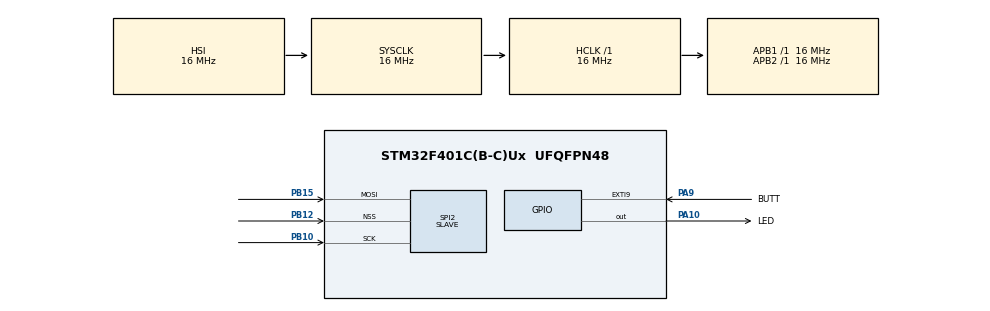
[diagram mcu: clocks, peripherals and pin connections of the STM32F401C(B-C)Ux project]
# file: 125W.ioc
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Mcu.Family=STM32F4
Mcu.Name=STM32F401C(B-C)Ux
Mcu.Package=UFQFPN48
NVIC.EXTI9_5_IRQn=true\:8\:0\:true\:false\:true\:true\:true\:true
NVIC.PriorityGroup=NVIC_PRIORITYGROUP_4
NVIC.SPI2_IRQn=true\:5\:0\:true\:false\:true\:true\:true\:true
PA10.GPIO_Label=LED
PA10.PinState=GPIO_PIN_SET
PA10.Signal=GPIO_Output
PA9.GPIO_Label=BUTT
PA9.GPIO_ModeDefaultEXTI=GPIO_MODE_IT_RISING
PA9.Signal=GPXTI9
PB10.Mode=RX_Only_Simplex_Unidirect_Slave
PB10.Signal=SPI2_SCK
PB12.Mode=NSS_Signal_Hard_Input
PB12.Signal=SPI2_NSS
PB15.Mode=RX_Only_Simplex_Unidirect_Slave
PB15.Signal=SPI2_MOSI
ProjectManager.HeapSize=0x200
ProjectManager.StackSize=0x400
ProjectManager.TargetToolchain=STM32CubeIDE
RCC.AHBFreq_Value=16000000
RCC.APB1Freq_Value=16000000
RCC.APB2Freq_Value=16000000
RCC.CortexFreq_Value=16000000
RCC.HSE_VALUE=25000000
RCC.HSI_VALUE=16000000
RCC.LSE_VALUE=32768
RCC.SYSCLKFreq_VALUE=16000000
RCC.VCOOutputFreq_Value=192000000
SPI2.Direction=SPI_DIRECTION_2LINES_RXONLY
SPI2.Mode=SPI_MODE_SLAVE
SPI2.VirtualNSS=VM_NSSHARD
SPI2.VirtualType=VM_SLAVE
board=custom

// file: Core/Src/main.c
/* USER CODE BEGIN Header */
/**
  ******************************************************************************
  * @file           : main.c
  * @brief          : Main program body
  ******************************************************************************
  * @attention
  *
  * Copyright (c) 2024 STMicroelectronics.
  * All rights reserved.
  *
  * This software is licensed under terms that can be found in the LICENSE file
  * in the root directory of this software component.
  * If no LICENSE file comes with this software, it is provided AS-IS.
  *
  ******************************************************************************
  */
/* USER CODE END Header */
#include "main.h"

SPI_HandleTypeDef hspi2;

/* USER CODE BEGIN PV */
uint8_t rx_buff = 0x00;
/* USER CODE END PV */

void SystemClock_Config(void);
static void MX_GPIO_Init(void);
static void MX_SPI2_Init(void);

int main(void)
{

  /* MCU Configuration--------------------------------------------------------*/

  /* Reset of all peripherals, Initializes the Flash interface and the Systick. */
  HAL_Init();

  /* Configure the system clock */
  SystemClock_Config();

  /* Initialize all configured peripherals */
  MX_GPIO_Init();
  MX_SPI2_Init();
  /* USER CODE BEGIN 2 */
  //uint8_t rx_buff = 0xff;

  HAL_SPI_Receive_IT (&hspi2, &rx_buff, sizeof(rx_buff));
  //HAL_SPI_Receive_IT (&hspi2, rx_buff, sizeof(rx_buff));
  //HAL_GPIO_ReadPin(BUTT_GPIOx_Port, BUTT_Pin);
  /* USER CODE END 2 */

  /* Infinite loop */
  /* USER CODE BEGIN WHILE */
  while (1)
  {
	  if (rx_buff) HAL_GPIO_WritePin(LED_GPIO_Port, LED_Pin, 0);
    /* USER CODE BEGIN 3 */
	 // if (rx_buff) HAL_GPIO_WritePin(LED_GPIO_Port, LED_Pin, 0);
  }
  /* USER CODE END 3 */
    /* USER CODE END WHILE */

  }

void SystemClock_Config(void)
{
  RCC_OscInitTypeDef RCC_OscInitStruct = {0};
  RCC_ClkInitTypeDef RCC_ClkInitStruct = {0};

  /** Configure the main internal regulator output voltage
  */
  __HAL_RCC_PWR_CLK_ENABLE();
  __HAL_PWR_VOLTAGESCALING_CONFIG(PWR_REGULATOR_VOLTAGE_SCALE2);

  /** Initializes the RCC Oscillators according to the specified parameters
  * in the RCC_OscInitTypeDef structure.
  */
  RCC_OscInitStruct.OscillatorType = RCC_OSCILLATORTYPE_HSI;
  RCC_OscInitStruct.HSIState = RCC_HSI_ON;
  RCC_OscInitStruct.HSICalibrationValue = RCC_HSICALIBRATION_DEFAULT;
  RCC_OscInitStruct.PLL.PLLState = RCC_PLL_NONE;
  if (HAL_RCC_OscConfig(&RCC_OscInitStruct) != HAL_OK)
  {
    Error_Handler();
  }

  /** Initializes the CPU, AHB and APB buses clocks
  */
  RCC_ClkInitStruct.ClockType = RCC_CLOCKTYPE_HCLK|RCC_CLOCKTYPE_SYSCLK
                              |RCC_CLOCKTYPE_PCLK1|RCC_CLOCKTYPE_PCLK2;
  RCC_ClkInitStruct.SYSCLKSource = RCC_SYSCLKSOURCE_HSI;
  RCC_ClkInitStruct.AHBCLKDivider = RCC_SYSCLK_DIV1;
  RCC_ClkInitStruct.APB1CLKDivider = RCC_HCLK_DIV1;
  RCC_ClkInitStruct.APB2CLKDivider = RCC_HCLK_DIV1;

  if (HAL_RCC_ClockConfig(&RCC_ClkInitStruct, FLASH_LATENCY_0) != HAL_OK)
  {
    Error_Handler();
  }
}

static void MX_SPI2_Init(void)
{

  /* SPI2 parameter configuration*/
  hspi2.Instance = SPI2;
  hspi2.Init.Mode = SPI_MODE_SLAVE;
  hspi2.Init.Direction = SPI_DIRECTION_2LINES_RXONLY;
  hspi2.Init.DataSize = SPI_DATASIZE_8BIT;
  hspi2.Init.CLKPolarity = SPI_POLARITY_LOW;
  hspi2.Init.CLKPhase = SPI_PHASE_1EDGE;
  hspi2.Init.NSS = SPI_NSS_HARD_INPUT;
  hspi2.Init.FirstBit = SPI_FIRSTBIT_MSB;
  hspi2.Init.TIMode = SPI_TIMODE_DISABLE;
  hspi2.Init.CRCCalculation = SPI_CRCCALCULATION_DISABLE;
  hspi2.Init.CRCPolynomial = 10;
  if (HAL_SPI_Init(&hspi2) != HAL_OK)
  {
    Error_Handler();
  }

}

static void MX_GPIO_Init(void)
{
  GPIO_InitTypeDef GPIO_InitStruct = {0};

  /* GPIO Ports Clock Enable */
  __HAL_RCC_GPIOB_CLK_ENABLE();
  __HAL_RCC_GPIOA_CLK_ENABLE();

  /*Configure GPIO pin Output Level */
  HAL_GPIO_WritePin(LED_GPIO_Port, LED_Pin, GPIO_PIN_SET);

  /*Configure GPIO pin : BUTT_Pin */
  GPIO_InitStruct.Pin = BUTT_Pin;
  GPIO_InitStruct.Mode = GPIO_MODE_IT_RISING;
  GPIO_InitStruct.Pull = GPIO_NOPULL;
  HAL_GPIO_Init(BUTT_GPIO_Port, &GPIO_InitStruct);

  /*Configure GPIO pin : LED_Pin */
  GPIO_InitStruct.Pin = LED_Pin;
  GPIO_InitStruct.Mode = GPIO_MODE_OUTPUT_PP;
  GPIO_InitStruct.Pull = GPIO_NOPULL;
  GPIO_InitStruct.Speed = GPIO_SPEED_FREQ_LOW;
  HAL_GPIO_Init(LED_GPIO_Port, &GPIO_InitStruct);

  /* EXTI interrupt init*/
  HAL_NVIC_SetPriority(EXTI9_5_IRQn, 8, 0);
  HAL_NVIC_EnableIRQ(EXTI9_5_IRQn);

}

/* USER CODE BEGIN 4 */
void HAL_GPIO_EXTI_Callback(uint16_t pin)
{
	if(pin==BUTT_Pin)
	{
		//HAL_GPIO_TogglePin(LED_GPIO_Port, LED_Pin);
		rx_buff = 0x00;
		HAL_GPIO_WritePin(LED_GPIO_Port, LED_Pin, 1);
	}
}
/* USER CODE END 4 */

void Error_Handler(void)
{
  __disable_irq();
  while (1)
  {
  }
}
